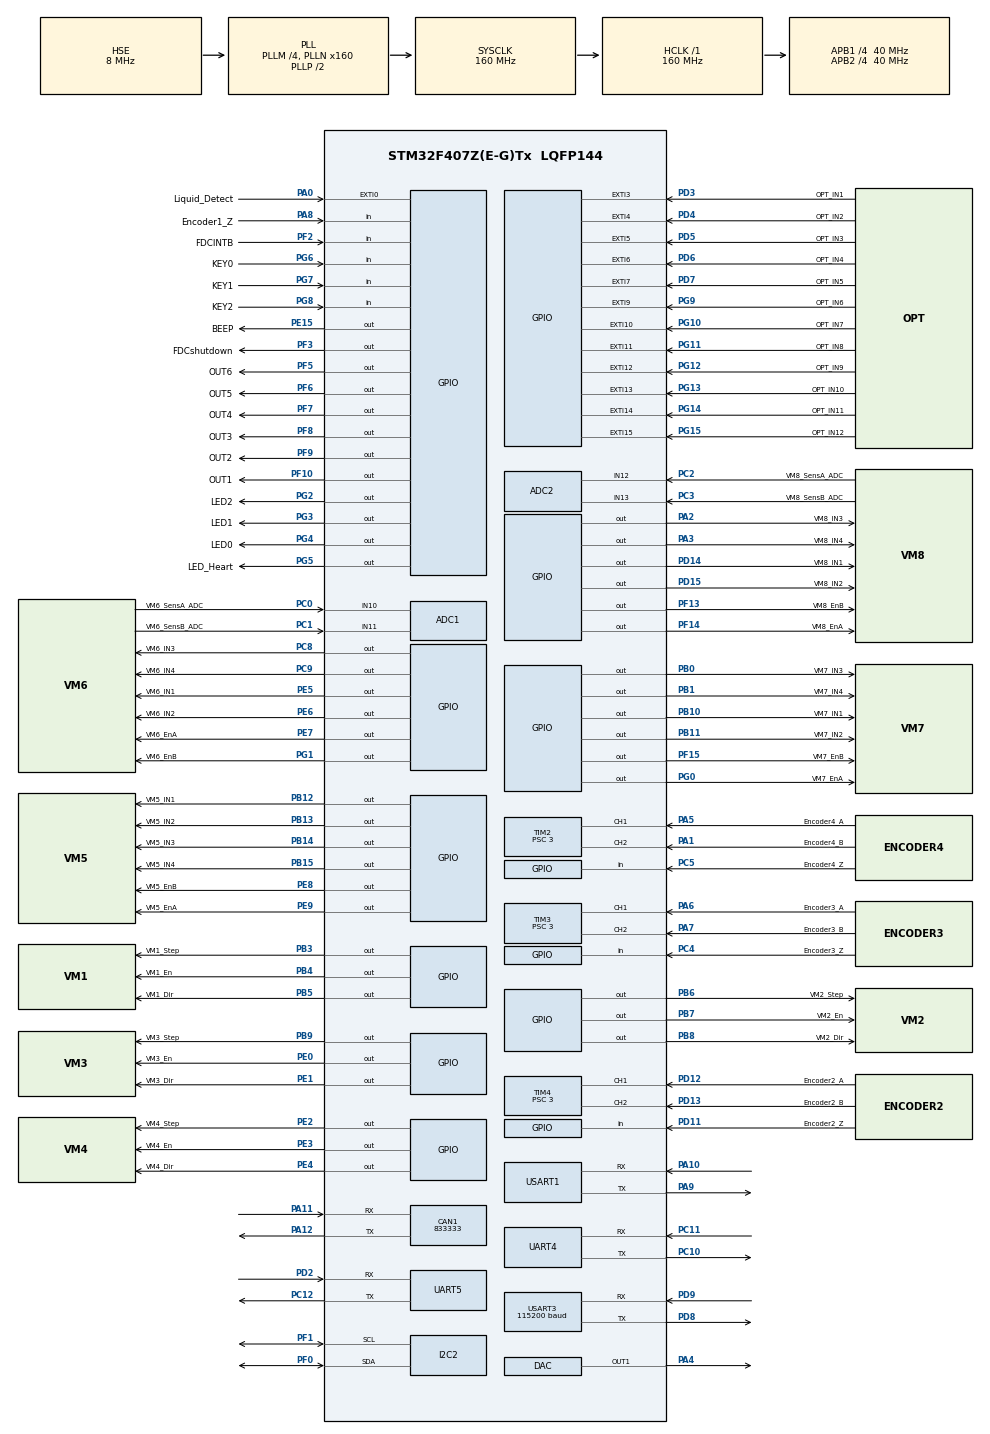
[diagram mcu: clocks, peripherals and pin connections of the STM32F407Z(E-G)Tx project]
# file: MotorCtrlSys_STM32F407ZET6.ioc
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ADC1.Channel-3\#ChannelRegularConversion=ADC_CHANNEL_10
ADC1.ClockPrescaler=ADC_CLOCK_SYNC_PCLK_DIV2
ADC1.ContinuousConvMode=DISABLE
ADC1.DMAContinuousRequests=DISABLE
ADC1.DiscontinuousConvMode=DISABLE
ADC1.EOCSelection=ADC_EOC_SINGLE_CONV
ADC1.NbrOfConversion=1
ADC1.NbrOfConversionFlag=1
ADC1.Rank-3\#ChannelRegularConversion=1
ADC1.SamplingTime-3\#ChannelRegularConversion=ADC_SAMPLETIME_15CYCLES
ADC1.ScanConvMode=DISABLE
ADC1.master=1
ADC2.Channel-2\#ChannelRegularConversion=ADC_CHANNEL_12
ADC2.NbrOfConversionFlag=1
ADC2.Rank-2\#ChannelRegularConversion=1
ADC2.SamplingTime-2\#ChannelRegularConversion=ADC_SAMPLETIME_3CYCLES
CAN1.BS1=CAN_BS1_1TQ
CAN1.BS2=CAN_BS2_1TQ
CAN1.CalculateBaudRate=833333
CAN1.CalculateTimeBit=1200
CAN1.CalculateTimeQuantum=400.0
Dma.I2C2_RX.0.Direction=DMA_PERIPH_TO_MEMORY
Dma.I2C2_RX.0.FIFOMode=DMA_FIFOMODE_DISABLE
Dma.I2C2_RX.0.Instance=DMA1_Stream2
Dma.I2C2_RX.0.MemDataAlignment=DMA_MDATAALIGN_BYTE
Dma.I2C2_RX.0.MemInc=DMA_MINC_ENABLE
Dma.I2C2_RX.0.Mode=DMA_CIRCULAR
Dma.I2C2_RX.0.PeriphDataAlignment=DMA_PDATAALIGN_BYTE
Dma.I2C2_RX.0.PeriphInc=DMA_PINC_DISABLE
Dma.I2C2_RX.0.Priority=DMA_PRIORITY_MEDIUM
Dma.Request0=I2C2_RX
FREERTOS.Tasks01=defaultTask,8,128,StartDefaultTask,Default,NULL,Dynamic,NULL,NULL;messageTask,24,512,StartmessageTask,As weak,NULL,Dynamic,NULL,NULL;myTask03,24,512,StartTask03,As weak,NULL,Dynamic,NULL,NULL;DetectionTask,8,512,StartDetectionTask,As weak,NULL,Dynamic,NULL,NULL
FREERTOS.configUSE_NEWLIB_REENTRANT=1
Mcu.Family=STM32F4
Mcu.Name=STM32F407Z(E-G)Tx
Mcu.Package=LQFP144
NVIC.DMA1_Stream2_IRQn=true\:7\:0\:true\:false\:true\:true\:false\:true\:true
NVIC.EXTI0_IRQn=true\:5\:0\:false\:false\:true\:true\:true\:true\:true
NVIC.EXTI15_10_IRQn=true\:5\:0\:false\:false\:true\:true\:true\:true\:true
NVIC.EXTI3_IRQn=true\:5\:0\:true\:false\:true\:true\:true\:true\:true
NVIC.EXTI4_IRQn=true\:5\:0\:false\:false\:true\:true\:true\:true\:true
NVIC.EXTI9_5_IRQn=true\:5\:0\:false\:false\:true\:true\:true\:true\:true
NVIC.I2C2_ER_IRQn=true\:5\:0\:true\:false\:true\:true\:true\:true\:true
NVIC.I2C2_EV_IRQn=true\:5\:0\:true\:false\:true\:true\:true\:true\:true
NVIC.PriorityGroup=NVIC_PRIORITYGROUP_4
NVIC.TIM1_BRK_TIM9_IRQn=true\:5\:0\:false\:false\:true\:true\:true\:true\:true
NVIC.TIM1_TRG_COM_TIM11_IRQn=true\:5\:0\:false\:false\:true\:true\:true\:true\:true
NVIC.TIM1_UP_TIM10_IRQn=true\:5\:0\:false\:false\:true\:false\:false\:true\:true
NVIC.TIM3_IRQn=true\:5\:0\:false\:false\:true\:true\:true\:true\:true
NVIC.TIM4_IRQn=true\:5\:0\:true\:false\:true\:true\:true\:true\:true
NVIC.TIM6_DAC_IRQn=true\:7\:0\:true\:false\:true\:true\:true\:true\:true
NVIC.TIM7_IRQn=true\:6\:0\:true\:false\:true\:true\:true\:true\:true
NVIC.TIM8_BRK_TIM12_IRQn=true\:5\:0\:false\:false\:true\:true\:true\:true\:true
NVIC.TIM8_TRG_COM_TIM14_IRQn=true\:5\:0\:false\:false\:true\:true\:true\:true\:true
NVIC.TIM8_UP_TIM13_IRQn=true\:5\:0\:false\:false\:true\:true\:true\:true\:true
NVIC.TimeBase=TIM1_UP_TIM10_IRQn
NVIC.TimeBaseIP=TIM1
NVIC.UART5_IRQn=true\:9\:0\:true\:false\:true\:true\:true\:true\:true
PA0-WKUP.GPIO_Label=Liquid_Detect
PA0-WKUP.GPIO_ModeDefaultEXTI=GPIO_MODE_IT_RISING_FALLING
PA0-WKUP.GPIO_PuPd=GPIO_PULLUP
PA0-WKUP.Signal=GPXTI0
PA1.GPIO_Label=Encoder4_B
PA1.Signal=S_TIM2_CH2
PA10.Mode=Asynchronous
PA10.Signal=USART1_RX
PA11.Mode=CAN_Activate
PA11.Signal=CAN1_RX
PA12.Mode=CAN_Activate
PA12.Signal=CAN1_TX
PA13.Mode=Serial_Wire
PA13.Signal=SYS_JTMS-SWDIO
PA14.Mode=Serial_Wire
PA14.Signal=SYS_JTCK-SWCLK
PA2.GPIO_Label=VM8_IN3
PA2.GPIO_Speed=GPIO_SPEED_FREQ_HIGH
PA2.Signal=GPIO_Output
PA3.GPIO_Label=VM8_IN4
PA3.GPIO_Speed=GPIO_SPEED_FREQ_HIGH
PA3.Signal=GPIO_Output
PA4.Signal=COMP_DAC1_group
PA5.GPIO_Label=Encoder4_A
PA5.Signal=S_TIM2_CH1_ETR
PA6.GPIO_Label=Encoder3_A
PA6.Signal=S_TIM3_CH1
PA7.GPIO_Label=Encoder3_B
PA7.Signal=S_TIM3_CH2
PA8.GPIO_Label=Encoder1_Z
PA8.Signal=GPIO_Input
PA9.Mode=Asynchronous
PA9.Signal=USART1_TX
PB0.GPIO_Label=VM7_IN3
PB0.GPIO_Speed=GPIO_SPEED_FREQ_HIGH
PB0.Signal=GPIO_Output
PB1.GPIO_Label=VM7_IN4
PB1.GPIO_Speed=GPIO_SPEED_FREQ_HIGH
PB1.Signal=GPIO_Output
PB10.GPIO_Label=VM7_IN1
PB10.GPIO_Speed=GPIO_SPEED_FREQ_HIGH
PB10.Signal=GPIO_Output
PB11.GPIO_Label=VM7_IN2
PB11.GPIO_Speed=GPIO_SPEED_FREQ_HIGH
PB11.Signal=GPIO_Output
PB12.GPIO_Label=VM5_IN1
PB12.GPIO_Speed=GPIO_SPEED_FREQ_HIGH
PB12.Signal=GPIO_Output
PB13.GPIO_Label=VM5_IN2
PB13.GPIO_Speed=GPIO_SPEED_FREQ_HIGH
PB13.Signal=GPIO_Output
PB14.GPIO_Label=VM5_IN3
PB14.GPIO_Speed=GPIO_SPEED_FREQ_HIGH
PB14.Signal=GPIO_Output
PB15.GPIO_Label=VM5_IN4
PB15.GPIO_Speed=GPIO_SPEED_FREQ_HIGH
PB15.Signal=GPIO_Output
PB3.GPIO_Label=VM1_Step
PB3.GPIO_Speed=GPIO_SPEED_FREQ_VERY_HIGH
PB3.Signal=GPIO_Output
PB4.GPIO_Label=VM1_En
PB4.PinState=GPIO_PIN_SET
PB4.Signal=GPIO_Output
PB5.GPIO_Label=VM1_Dir
PB5.Signal=GPIO_Output
PB6.GPIO_Label=VM2_Step
PB6.GPIO_Speed=GPIO_SPEED_FREQ_VERY_HIGH
PB6.Signal=GPIO_Output
PB7.GPIO_Label=VM2_En
PB7.PinState=GPIO_PIN_SET
PB7.Signal=GPIO_Output
PB8.GPIO_Label=VM2_Dir
PB8.Signal=GPIO_Output
PB9.GPIO_Label=VM3_Step
PB9.GPIO_Speed=GPIO_SPEED_FREQ_VERY_HIGH
PB9.Signal=GPIO_Output
PC0.GPIO_Label=VM6_SensA_ADC
PC0.Signal=ADCx_IN10
PC1.GPIO_Label=VM6_SensB_ADC
PC1.Signal=ADCx_IN11
PC10.Mode=Asynchronous
PC10.Signal=UART4_TX
PC11.Mode=Asynchronous
PC11.Signal=UART4_RX
PC12.Mode=Asynchronous
PC12.Signal=UART5_TX
PC14-OSC32_IN.Mode=LSE-External-Oscillator
PC14-OSC32_IN.Signal=RCC_OSC32_IN
PC15-OSC32_OUT.Mode=LSE-External-Oscillator
PC15-OSC32_OUT.Signal=RCC_OSC32_OUT
PC2.GPIO_Label=VM8_SensA_ADC
PC2.Signal=ADCx_IN12
PC3.GPIO_Label=VM8_SensB_ADC
PC3.Signal=ADCx_IN13
PC4.GPIO_Label=Encoder3_Z
PC4.Signal=GPIO_Input
PC5.GPIO_Label=Encoder4_Z
PC5.Signal=GPIO_Input
PC8.GPIO_Label=VM6_IN3
PC8.GPIO_Speed=GPIO_SPEED_FREQ_HIGH
PC8.Signal=GPIO_Output
PC9.GPIO_Label=VM6_IN4
PC9.GPIO_Speed=GPIO_SPEED_FREQ_HIGH
PC9.Signal=GPIO_Output
PD11.GPIO_Label=Encoder2_Z
PD11.Signal=GPIO_Input
PD12.GPIO_Label=Encoder2_A
PD12.Signal=S_TIM4_CH1
PD13.GPIO_Label=Encoder2_B
PD13.Signal=S_TIM4_CH2
PD14.GPIO_Label=VM8_IN1
PD14.GPIO_Speed=GPIO_SPEED_FREQ_HIGH
PD14.Signal=GPIO_Output
PD15.GPIO_Label=VM8_IN2
PD15.GPIO_Speed=GPIO_SPEED_FREQ_HIGH
PD15.Signal=GPIO_Output
PD2.Mode=Asynchronous
PD2.Signal=UART5_RX
PD3.GPIO_Label=OPT_IN1
PD3.GPIO_ModeDefaultEXTI=GPIO_MODE_IT_RISING_FALLING
PD3.Signal=GPXTI3
PD4.GPIO_Label=OPT_IN2
PD4.GPIO_ModeDefaultEXTI=GPIO_MODE_IT_RISING_FALLING
PD4.Signal=GPXTI4
PD5.GPIO_Label=OPT_IN3
PD5.GPIO_ModeDefaultEXTI=GPIO_MODE_IT_RISING_FALLING
PD5.Signal=GPXTI5
PD6.GPIO_Label=OPT_IN4
PD6.GPIO_ModeDefaultEXTI=GPIO_MODE_IT_RISING_FALLING
PD6.Signal=GPXTI6
PD7.GPIO_Label=OPT_IN5
PD7.GPIO_ModeDefaultEXTI=GPIO_MODE_IT_RISING_FALLING
PD7.Signal=GPXTI7
PD8.Mode=Asynchronous
PD8.Signal=USART3_TX
PD9.Mode=Asynchronous
PD9.Signal=USART3_RX
PE0.GPIO_Label=VM3_En
PE0.PinState=GPIO_PIN_SET
PE0.Signal=GPIO_Output
PE1.GPIO_Label=VM3_Dir
PE1.Signal=GPIO_Output
PE15.GPIO_Label=BEEP
PE15.Signal=GPIO_Output
PE2.GPIO_Label=VM4_Step
PE2.GPIO_Speed=GPIO_SPEED_FREQ_VERY_HIGH
PE2.Signal=GPIO_Output
PE3.GPIO_Label=VM4_En
PE3.PinState=GPIO_PIN_SET
PE3.Signal=GPIO_Output
PE4.GPIO_Label=VM4_Dir
PE4.Signal=GPIO_Output
PE5.GPIO_Label=VM6_IN1
PE5.GPIO_Speed=GPIO_SPEED_FREQ_HIGH
PE5.Signal=GPIO_Output
PE6.GPIO_Label=VM6_IN2
PE6.GPIO_Speed=GPIO_SPEED_FREQ_HIGH
PE6.Signal=GPIO_Output
PE7.GPIO_Label=VM6_EnA
PE7.GPIO_ModeDefaultOutputPP=GPIO_MODE_OUTPUT_PP
PE7.GPIO_PuPd=GPIO_PULLDOWN
PE7.GPIO_Speed=GPIO_SPEED_FREQ_LOW
PE7.PinState=GPIO_PIN_RESET
PE7.Signal=GPIO_Output
PE8.GPIO_Label=VM5_EnB
PE8.GPIO_ModeDefaultOutputPP=GPIO_MODE_OUTPUT_PP
PE8.GPIO_PuPd=GPIO_PULLDOWN
PE8.GPIO_Speed=GPIO_SPEED_FREQ_LOW
PE8.PinState=GPIO_PIN_RESET
PE8.Signal=GPIO_Output
PE9.GPIO_Label=VM5_EnA
PE9.GPIO_ModeDefaultOutputPP=GPIO_MODE_OUTPUT_PP
PE9.GPIO_PuPd=GPIO_PULLDOWN
PE9.GPIO_Speed=GPIO_SPEED_FREQ_LOW
PE9.PinState=GPIO_PIN_RESET
PE9.Signal=GPIO_Output
PF0.Mode=I2C
PF0.Signal=I2C2_SDA
PF1.Mode=I2C
PF1.Signal=I2C2_SCL
PF10.GPIO_Label=OUT1
PF10.GPIO_ModeDefaultOutputPP=GPIO_MODE_OUTPUT_PP
PF10.GPIO_PuPd=GPIO_PULLDOWN
PF10.GPIO_Speed=GPIO_SPEED_FREQ_LOW
PF10.PinState=GPIO_PIN_RESET
PF10.Signal=GPIO_Output
PF13.GPIO_Label=VM8_EnB
PF13.GPIO_ModeDefaultOutputPP=GPIO_MODE_OUTPUT_PP
PF13.GPIO_PuPd=GPIO_PULLDOWN
PF13.GPIO_Speed=GPIO_SPEED_FREQ_LOW
PF13.PinState=GPIO_PIN_RESET
PF13.Signal=GPIO_Output
PF14.GPIO_Label=VM8_EnA
PF14.GPIO_ModeDefaultOutputPP=GPIO_MODE_OUTPUT_PP
PF14.GPIO_PuPd=GPIO_PULLDOWN
PF14.GPIO_Speed=GPIO_SPEED_FREQ_LOW
PF14.PinState=GPIO_PIN_RESET
PF14.Signal=GPIO_Output
PF15.GPIO_Label=VM7_EnB
PF15.GPIO_ModeDefaultOutputPP=GPIO_MODE_OUTPUT_PP
PF15.GPIO_PuPd=GPIO_PULLDOWN
PF15.GPIO_Speed=GPIO_SPEED_FREQ_LOW
PF15.PinState=GPIO_PIN_RESET
PF15.Signal=GPIO_Output
PF2.GPIO_Label=FDCINTB
PF2.Signal=GPIO_Input
PF3.GPIO_Label=FDCshutdown
PF3.Signal=GPIO_Output
PF5.GPIO_Label=OUT6
PF5.GPIO_ModeDefaultOutputPP=GPIO_MODE_OUTPUT_PP
PF5.GPIO_PuPd=GPIO_PULLDOWN
PF5.GPIO_Speed=GPIO_SPEED_FREQ_LOW
PF5.PinState=GPIO_PIN_RESET
PF5.Signal=GPIO_Output
PF6.GPIO_Label=OUT5
PF6.GPIO_ModeDefaultOutputPP=GPIO_MODE_OUTPUT_PP
PF6.GPIO_PuPd=GPIO_PULLDOWN
PF6.GPIO_Speed=GPIO_SPEED_FREQ_LOW
PF6.PinState=GPIO_PIN_RESET
PF6.Signal=GPIO_Output
PF7.GPIO_Label=OUT4
PF7.GPIO_ModeDefaultOutputPP=GPIO_MODE_OUTPUT_PP
PF7.GPIO_PuPd=GPIO_PULLDOWN
PF7.GPIO_Speed=GPIO_SPEED_FREQ_LOW
PF7.PinState=GPIO_PIN_RESET
PF7.Signal=GPIO_Output
PF8.GPIO_Label=OUT3
PF8.GPIO_ModeDefaultOutputPP=GPIO_MODE_OUTPUT_PP
PF8.GPIO_PuPd=GPIO_PULLDOWN
PF8.GPIO_Speed=GPIO_SPEED_FREQ_LOW
PF8.PinState=GPIO_PIN_RESET
PF8.Signal=GPIO_Output
PF9.GPIO_Label=OUT2
PF9.GPIO_ModeDefaultOutputPP=GPIO_MODE_OUTPUT_PP
PF9.GPIO_PuPd=GPIO_PULLDOWN
PF9.GPIO_Speed=GPIO_SPEED_FREQ_LOW
PF9.PinState=GPIO_PIN_RESET
PF9.Signal=GPIO_Output
PG0.GPIO_Label=VM7_EnA
PG0.GPIO_ModeDefaultOutputPP=GPIO_MODE_OUTPUT_PP
PG0.GPIO_PuPd=GPIO_PULLDOWN
PG0.GPIO_Speed=GPIO_SPEED_FREQ_LOW
PG0.PinState=GPIO_PIN_RESET
PG0.Signal=GPIO_Output
PG1.GPIO_Label=VM6_EnB
PG1.GPIO_ModeDefaultOutputPP=GPIO_MODE_OUTPUT_PP
PG1.GPIO_PuPd=GPIO_PULLDOWN
PG1.GPIO_Speed=GPIO_SPEED_FREQ_LOW
PG1.PinState=GPIO_PIN_RESET
PG1.Signal=GPIO_Output
PG10.GPIO_Label=OPT_IN7
PG10.GPIO_ModeDefaultEXTI=GPIO_MODE_IT_RISING_FALLING
PG10.Signal=GPXTI10
PG11.GPIO_Label=OPT_IN8
PG11.GPIO_ModeDefaultEXTI=GPIO_MODE_IT_RISING_FALLING
PG11.Signal=GPXTI11
PG12.GPIO_Label=OPT_IN9
PG12.GPIO_ModeDefaultEXTI=GPIO_MODE_IT_RISING_FALLING
PG12.Signal=GPXTI12
PG13.GPIO_Label=OPT_IN10
PG13.GPIO_ModeDefaultEXTI=GPIO_MODE_IT_RISING_FALLING
PG13.Signal=GPXTI13
PG14.GPIO_Label=OPT_IN11
PG14.GPIO_ModeDefaultEXTI=GPIO_MODE_IT_RISING_FALLING
PG14.Signal=GPXTI14
PG15.GPIO_Label=OPT_IN12
PG15.GPIO_ModeDefaultEXTI=GPIO_MODE_IT_RISING_FALLING
PG15.Signal=GPXTI15
PG2.GPIO_Label=LED2
PG2.PinState=GPIO_PIN_SET
PG2.Signal=GPIO_Output
PG3.GPIO_Label=LED1
PG3.PinState=GPIO_PIN_SET
PG3.Signal=GPIO_Output
PG4.GPIO_Label=LED0
PG4.PinState=GPIO_PIN_SET
PG4.Signal=GPIO_Output
PG5.GPIO_Label=LED_Heart
PG5.Signal=GPIO_Output
PG6.GPIO_Label=KEY0
PG6.GPIO_PuPd=GPIO_PULLUP
PG6.Signal=GPIO_Input
PG7.GPIO_Label=KEY1
PG7.GPIO_PuPd=GPIO_PULLUP
PG7.Signal=GPIO_Input
PG8.GPIO_Label=KEY2
PG8.GPIO_PuPd=GPIO_PULLUP
PG8.Signal=GPIO_Input
PG9.GPIO_Label=OPT_IN6
PG9.GPIO_ModeDefaultEXTI=GPIO_MODE_IT_RISING_FALLING
PG9.Signal=GPXTI9
PH0-OSC_IN.Mode=HSE-External-Oscillator
PH0-OSC_IN.Signal=RCC_OSC_IN
PH1-OSC_OUT.Mode=HSE-External-Oscillator
PH1-OSC_OUT.Signal=RCC_OSC_OUT
ProjectManager.HeapSize=0x200
ProjectManager.StackSize=0x400
ProjectManager.TargetToolchain=STM32CubeIDE
RCC.48MHZClocksFreq_Value=80000000
RCC.AHBFreq_Value=160000000
RCC.APB1CLKDivider=RCC_HCLK_DIV4
RCC.APB1Freq_Value=40000000
RCC.APB1TimFreq_Value=80000000
RCC.APB2CLKDivider=RCC_HCLK_DIV4
RCC.APB2Freq_Value=40000000
RCC.APB2TimFreq_Value=80000000
RCC.CortexFreq_Value=160000000
RCC.HCLKFreq_Value=160000000
RCC.HSE_VALUE=8000000
RCC.HSI_VALUE=16000000
RCC.PLLM=4
RCC.PLLN=160
RCC.PLLSourceVirtual=RCC_PLLSOURCE_HSE
RCC.SYSCLKFreq_VALUE=160000000
RCC.SYSCLKSource=RCC_SYSCLKSOURCE_PLLCLK
RCC.VCOOutputFreq_Value=320000000
SH.ADCx_IN10.0=ADC1_IN10,IN10
SH.ADCx_IN11.0=ADC1_IN11,IN11
SH.ADCx_IN12.0=ADC2_IN12,IN12
SH.ADCx_IN13.0=ADC2_IN13,IN13
SH.COMP_DAC1_group.0=DAC_OUT1,DAC_OUT1
SH.S_TIM2_CH1_ETR.0=TIM2_CH1,Encoder_Interface
SH.S_TIM2_CH2.0=TIM2_CH2,Encoder_Interface
SH.S_TIM3_CH1.0=TIM3_CH1,Encoder_Interface
SH.S_TIM3_CH2.0=TIM3_CH2,Encoder_Interface
SH.S_TIM4_CH1.0=TIM4_CH1,Encoder_Interface
SH.S_TIM4_CH2.0=TIM4_CH2,Encoder_Interface
TIM10.Period=9
TIM10.Prescaler=79
TIM11.Period=9
TIM11.Prescaler=79
TIM12.Period=9
TIM12.Prescaler=79
TIM13.Period=9
TIM13.Prescaler=79
TIM14.Period=9
TIM14.Prescaler=79
TIM2.Period=65535
TIM2.Prescaler=3
TIM3.CounterMode=TIM_COUNTERMODE_UP
TIM3.EncoderMode=TIM_ENCODERMODE_TI12
TIM3.IC1Filter=15
TIM3.IC2Filter=15
TIM3.Prescaler=3
TIM4.EncoderMode=TIM_ENCODERMODE_TI12
TIM4.IC1Filter=15
TIM4.IC2Filter=15
TIM4.Period=65535
TIM4.Prescaler=3
TIM6.Period=9
TIM6.Prescaler=79
TIM7.Period=9
TIM7.Prescaler=79
TIM9.Period=99
TIM9.Prescaler=79
UART4.VirtualMode=Asynchronous
UART5.VirtualMode=Asynchronous
USART1.VirtualMode=VM_ASYNC
USART3.BaudRate=115200
USART3.VirtualMode=VM_ASYNC
VP_FREERTOS_VS_CMSIS_V2.Mode=CMSIS_V2
VP_SYS_VS_tim1.Mode=TIM1
VP_TIM10_VS_ClockSourceINT.Mode=Enable_Timer
VP_TIM11_VS_ClockSourceINT.Mode=Enable_Timer
VP_TIM12_VS_ClockSourceINT.Mode=Internal
VP_TIM13_VS_ClockSourceINT.Mode=Enable_Timer
VP_TIM14_VS_ClockSourceINT.Mode=Enable_Timer
VP_TIM6_VS_ClockSourceINT.Mode=Enable_Timer
VP_TIM7_VS_ClockSourceINT.Mode=Enable_Timer
VP_TIM9_VS_ClockSourceINT.Mode=Internal
board=custom

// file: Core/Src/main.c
/* USER CODE BEGIN Header */
/**
  ******************************************************************************
  * @file           : main.c
  * @brief          : Main program body
  ******************************************************************************
  * @attention
  *
  * Copyright (c) 2022 STMicroelectronics.
  * All rights reserved.
  *
  * This software is licensed under terms that can be found in the LICENSE file
  * in the root directory of this software component.
  * If no LICENSE file comes with this software, it is provided AS-IS.
  *
  ******************************************************************************
  */
/* USER CODE END Header */
#include "main.h"
#include "cmsis_os.h"
#include "adc.h"
#include "can.h"
#include "dac.h"
#include "dma.h"
#include "i2c.h"
#include "tim.h"
#include "usart.h"
#include "gpio.h"

/* USER CODE BEGIN PTD */
#ifdef __GNUC__
#define PUTCHAR_PROTOTYPE int __io_putchar(int ch)
#else
#define PUTCHAR_PROTOTYPE int fputc(int ch, FILE *f)
#endif

PUTCHAR_PROTOTYPE
{
	HAL_UART_Transmit(&huart5, (uint8_t*)&ch,1,HAL_MAX_DELAY);
    return ch;
}
/* USER CODE END PTD */

void SystemClock_Config(void);
void MX_FREERTOS_Init(void);

int main(void)
{

  /* MCU Configuration--------------------------------------------------------*/

  /* Reset of all peripherals, Initializes the Flash interface and the Systick. */
  HAL_Init();

  /* USER CODE BEGIN Init */
  //HAL_Delay(6000);
  /* USER CODE END Init */

  /* Configure the system clock */
  SystemClock_Config();

  /* USER CODE BEGIN SysInit */
  MX_GPIO_Init();
  MX_DMA_Init();
  MX_CAN1_Init();
  MX_USART1_UART_Init();
  MX_DAC_Init();
  MX_TIM2_Init();
  MX_TIM3_Init();
  MX_TIM4_Init();
  MX_UART4_Init();
  MX_UART5_Init();
  MX_USART3_UART_Init();
  MX_ADC1_Init();
  MX_ADC2_Init();
  MX_I2C2_Init();
  MX_TIM10_Init();
  MX_TIM11_Init();
  MX_TIM13_Init();
  MX_TIM14_Init();
  MX_TIM9_Init();
  MX_TIM7_Init();
  MX_TIM6_Init();
  MX_TIM12_Init();
#ifdef XXX
  /* USER CODE END SysInit */

  /* Initialize all configured peripherals */
  MX_GPIO_Init();
  MX_DMA_Init();
  MX_USART1_UART_Init();
  MX_DAC_Init();
  MX_TIM2_Init();
  MX_TIM3_Init();
  MX_TIM4_Init();
  MX_UART4_Init();
  MX_UART5_Init();
  MX_USART3_UART_Init();
  MX_ADC1_Init();
  MX_ADC2_Init();
  MX_I2C2_Init();
  MX_TIM10_Init();
  MX_TIM11_Init();
  MX_TIM13_Init();
  MX_TIM14_Init();
  MX_TIM9_Init();
  MX_CAN1_Init();
  MX_TIM7_Init();
  MX_TIM6_Init();
  MX_TIM12_Init();
  /* USER CODE BEGIN 2 */
#endif
  ALL_Motors_Disable();

  /* USER CODE END 2 */

  /* Init scheduler */
  osKernelInitialize();  /* Call init function for freertos objects (in freertos.c) */
  MX_FREERTOS_Init();

  /* Start scheduler */
  osKernelStart();

  /* We should never get here as control is now taken by the scheduler */
  /* Infinite loop */
  while (1)
  {

  }
}

void SystemClock_Config(void)
{
  RCC_OscInitTypeDef RCC_OscInitStruct = {0};
  RCC_ClkInitTypeDef RCC_ClkInitStruct = {0};

  /** Configure the main internal regulator output voltage
  */
  __HAL_RCC_PWR_CLK_ENABLE();
  __HAL_PWR_VOLTAGESCALING_CONFIG(PWR_REGULATOR_VOLTAGE_SCALE1);

  /** Initializes the RCC Oscillators according to the specified parameters
  * in the RCC_OscInitTypeDef structure.
  */
  RCC_OscInitStruct.OscillatorType = RCC_OSCILLATORTYPE_HSE;
  RCC_OscInitStruct.HSEState = RCC_HSE_ON;
  RCC_OscInitStruct.PLL.PLLState = RCC_PLL_ON;
  RCC_OscInitStruct.PLL.PLLSource = RCC_PLLSOURCE_HSE;
  RCC_OscInitStruct.PLL.PLLM = 4;
  RCC_OscInitStruct.PLL.PLLN = 160;
  RCC_OscInitStruct.PLL.PLLP = RCC_PLLP_DIV2;
  RCC_OscInitStruct.PLL.PLLQ = 4;
  if (HAL_RCC_OscConfig(&RCC_OscInitStruct) != HAL_OK)
  {
    Error_Handler();
  }

  /** Initializes the CPU, AHB and APB buses clocks
  */
  RCC_ClkInitStruct.ClockType = RCC_CLOCKTYPE_HCLK|RCC_CLOCKTYPE_SYSCLK
                              |RCC_CLOCKTYPE_PCLK1|RCC_CLOCKTYPE_PCLK2;
  RCC_ClkInitStruct.SYSCLKSource = RCC_SYSCLKSOURCE_PLLCLK;
  RCC_ClkInitStruct.AHBCLKDivider = RCC_SYSCLK_DIV1;
  RCC_ClkInitStruct.APB1CLKDivider = RCC_HCLK_DIV4;
  RCC_ClkInitStruct.APB2CLKDivider = RCC_HCLK_DIV4;

  if (HAL_RCC_ClockConfig(&RCC_ClkInitStruct, FLASH_LATENCY_5) != HAL_OK)
  {
    Error_Handler();
  }
}

/* USER CODE BEGIN 4 */

uint32_t uart_reieve_timeoutCount = 0;
uint32_t Pluse_High = 2; // 高电平时10-20us
uint32_t timecount_TIM10 = 0;
uint32_t AccelDecelcount_TIM10 = 0;
uint32_t timecount_TIM11 = 0;
uint32_t AccelDecelcount_TIM11 = 0;
uint32_t timecount_TIM12 = 0;
uint32_t AccelDecelcount_TIM12 = 0;
uint8_t  Motor7_State = 1 ;
uint32_t timecount_TIM13 = 0;
uint32_t AccelDecelcount_TIM13 = 0;
uint32_t timecount_TIM14 = 0;
uint32_t AccelDecelcount_TIM14 = 0;
uint32_t timecount_TIM6 = 0;
uint32_t AccelDecelcount_TIM6 = 0;
uint8_t  Motor5_State = 1 ;
uint32_t timecount_TIM7 = 0;
uint32_t AccelDecelcount_TIM7 = 0;

#ifdef L298N_StepMotorCtrl
int  Motor6_State = 0 ;
#else
int  Motor6_State = 1 ;
#endif

//直流电机控制
uint32_t timecount_TIM12_DCM6 = 0 ;
uint32_t timecount_TIM12_DCM7 = 0 ;
uint32_t timecount_TIM12_DCM8 = 0 ;

/* USER CODE END 4 */

void HAL_TIM_PeriodElapsedCallback(TIM_HandleTypeDef *htim)
{
  if (htim->Instance == TIM1) {
    HAL_IncTick();
  }
  /* USER CODE BEGIN Callback 1 */

	if (htim->Instance == TIM9) {	// 计时器周期为0.1ms
		uart_reieve_timeoutCount++;
		if( (USART_RX_STA&0x8000) || (USART_RX_STA==0) ){	// 判断串口接收超时
			uart_reieve_timeoutCount = 0;
			HAL_TIM_Base_Stop_IT(&htim9);
		}
		else{
			if(uart_reieve_timeoutCount > 5000){
				printf("[WRONG] Data Input Timeout ! \r\n");
				uart_reieve_timeoutCount = 0;
				USART_RX_STA = 0;
				HAL_TIM_Base_Stop_IT(&htim9);
			}
		}
	}

	if (htim->Instance == TIM10)
	{
			timecount_TIM10++;
			AccelDecelcount_TIM10++;
			if(timecount_TIM10 <= Pluse_High)
			{
				Motorpluse1_High();
			}
			else if(timecount_TIM10 > Pluse_High)
			{
				Motorpluse1_Low();
			}
			if(timecount_TIM10 >= Motor[1].StepperSpeedTMR)
			{
				timecount_TIM10 = 0 ;
				Motor[1].NumberofSteps--;
				if (Motor[1].MotorDirection == 1){
					Motor[1].StepPosition++;
					if (Motor[1].StepPosition >= Motor[1].StepsInOneCircle){
						Motor[1].StepPosition = Motor[1].StepPosition - Motor[1].StepsInOneCircle ;
					}
				}
				else{
					Motor[1].StepPosition--;
					if (Motor[1].StepPosition < 0){
						Motor[1].StepPosition = Motor[1].StepPosition + Motor[1].StepsInOneCircle ;
					}
				}
			}
			if(Motor[1].StepPosition == Motor[1].TargetPosition)
			{
				Motor[1].Status = 0;
				printf("---Motor1 Steps Position:%ld---\r\n",Motor[1].StepPosition);
				HAL_TIM_Base_Stop_IT(&htim10);
			}
			else if (Motor[1].NumberofSteps <= 0){
				Motor[1].Status = 0;
				//printf("[WRONG]Motor1 Goto Target Position Failed!---Current_Position:%ld---\r\n",Motor[1].StepPosition);
				HAL_TIM_Base_Stop_IT(&htim10);
			}

			if (Motor[1].NumberofSteps > Motor[1].NumberofSteps_StopAccel)  // if.. begin Acceleration
			{
				if(AccelDecelcount_TIM10 >= Motor[1].AccelerationTimeTMR)
				{
					AccelDecelcount_TIM10=0;
					AccelDecel(ACCEL,&Motor[1]);
				}
			}
			else if (Motor[1].NumberofSteps < Motor[1].NumberofSteps_BeginDecel)  // if.. begin Deceleration
			{
				if(AccelDecelcount_TIM10 >= Motor[1].DecelerationTimeTMR)
				{
					AccelDecelcount_TIM10=0;
					AccelDecel(DECEL,&Motor[1]);
				}
			}

	}

	else if (htim->Instance == TIM11)
	{
			timecount_TIM11++;
			AccelDecelcount_TIM11++;
			if(timecount_TIM11 <= Pluse_High)
			{
				Motorpluse2_High();
			}
			else if(timecount_TIM11 > Pluse_High)
			{
				Motorpluse2_Low();
			}
			if(timecount_TIM11 >= Motor[2].StepperSpeedTMR)
			{
				timecount_TIM11 = 0 ;
				Motor[2].NumberofSteps--;
#ifndef JiaYangZhen_EncoderMode
				if (Motor[2].MotorDirection == 1){
					Motor[2].StepPosition++;
				}
				else{
					Motor[2].StepPosition--;
				}
#endif
			}

			if(Motor[2].StepPosition == Motor[2].TargetPosition){
				Motor[2].Status = 0;
				printf("---Motor2 Steps Position:%ld---\r\n",Motor[2].StepPosition);
				HAL_TIM_Base_Stop_IT(&htim11);
			}
			else if (Motor[2].NumberofSteps <= 0){
				Motor[2].Status = 0;
				//printf("[WRONG]Motor2 Goto Target Position Failed!---Current_Position:%ld---\r\n",Motor[2].StepPosition);
				HAL_TIM_Base_Stop_IT(&htim11);
			}

			if (Motor[2].NumberofSteps > Motor[2].NumberofSteps_StopAccel)
			{
				if(AccelDecelcount_TIM11 >= Motor[2].AccelerationTimeTMR)
				{
					AccelDecelcount_TIM11=0;
					AccelDecel(ACCEL,&Motor[2]);
				}
			}
			else if (Motor[2].NumberofSteps < Motor[2].NumberofSteps_BeginDecel)
			{
				if(AccelDecelcount_TIM11 >= Motor[2].DecelerationTimeTMR)
				{
					AccelDecelcount_TIM11=0;
					AccelDecel(DECEL,&Motor[2]);
				}
			}

	}

	else if (htim->Instance == TIM13)
	{
			timecount_TIM13++;
			AccelDecelcount_TIM13++;
#ifdef JiaYangZhen
//			if (Motor[3].StepPosition > 7000){
//				printf("[WRONG]OverTrip!!!,Motor[3].StepPosition:%ld\r\n",Motor[3].StepPosition);
//				Motor[3].Status = 0;
//				HAL_TIM_Base_Stop_IT(&htim13);
//			}

			if (DetectionTask_STATE == Cap0_Sample_State){
				switch (Follow_state){
				case 1:
					if(timecount_TIM13 <= Pluse_High){
						Motorpluse3_High();
					}
					else if(timecount_TIM13 > Pluse_High){
						Motorpluse3_Low();
					}
					if(timecount_TIM13 >= Motor[3].StepperSpeedTMR){
						timecount_TIM13 = 0 ;
#ifndef JiaYangZhen_EncoderMode
						Motor[3].StepPosition++;
#endif
					}
					break;
				case 2:
					timecount_TIM13 = 0 ;
					//使用IO输出模块进行液面�???????????�???????????
//					HAL_TIM_Base_Stop_IT(&htim13);
//					Motor[3].Status = 0;
					break;
				case 3:
					if(timecount_TIM13 <= Pluse_High){
						Motorpluse3_High();
					}
					else if(timecount_TIM13 > Pluse_High){
						Motorpluse3_Low();
					}
					if(timecount_TIM13 >= Motor[3].StepperSpeedTMR){
						timecount_TIM13 = 0 ;
#ifndef JiaYangZhen_EncoderMode
							Motor[3].StepPosition--;
#endif
					}
					break;
				}
			}
			else
#endif
			{
				if(timecount_TIM13 <= Pluse_High){
					Motorpluse3_High();
				}
				else if(timecount_TIM13 > Pluse_High){
					Motorpluse3_Low();
				}
				if(timecount_TIM13 >= Motor[3].StepperSpeedTMR){
					timecount_TIM13 = 0 ;
					Motor[3].NumberofSteps--;
#ifndef JiaYangZhen_EncoderMode
					if (Motor[3].MotorDirection == 1){
						Motor[3].StepPosition++;
					}
					else{
						Motor[3].StepPosition--;
					}
#endif
				}

				if(Motor[3].StepPosition == Motor[3].TargetPosition){
					Motor[3].Status = 0;
					printf("---Motor3 Steps Position:%ld---\r\n",Motor[3].StepPosition);
					HAL_TIM_Base_Stop_IT(&htim13);
				}
				else if (Motor[3].NumberofSteps <= 0){
					Motor[3].Status = 0;
					printf("[WRONG]Motor3 Goto Target Position Failed!---Current_Position:%ld---\r\n",Motor[3].StepPosition);
					HAL_TIM_Base_Stop_IT(&htim13);
				}

				if (Motor[3].NumberofSteps > Motor[3].NumberofSteps_StopAccel){
					if(AccelDecelcount_TIM13 >= Motor[3].AccelerationTimeTMR){
						AccelDecelcount_TIM13=0;
						AccelDecel(ACCEL,&Motor[3]);
					}
				}
				else if (Motor[3].NumberofSteps < Motor[3].NumberofSteps_BeginDecel){
					if(AccelDecelcount_TIM13 >= Motor[3].DecelerationTimeTMR){
						AccelDecelcount_TIM13=0;
						AccelDecel(DECEL,&Motor[3]);
					}
				}
			}

	}

	else if (htim->Instance == TIM14)
	{
			timecount_TIM14++;
			AccelDecelcount_TIM14++;
			if(timecount_TIM14 <= Pluse_High)
			{
				Motorpluse4_High();
			}
			else if(timecount_TIM14 > Pluse_High)
			{
				Motorpluse4_Low();
			}
			if(timecount_TIM14 >= Motor[4].StepperSpeedTMR)
			{
				timecount_TIM14 = 0 ;
				Motor[4].NumberofSteps--;
				if (Motor[4].MotorDirection == 1){
					Motor[4].StepPosition++;
				}
				else{
					Motor[4].StepPosition--;
				}
			}
			if(Motor[4].StepPosition == Motor[4].TargetPosition)
			{
				Motor[4].Status = 0;
				//printf("---Motor4 Steps Position:%ld---\r\n",Motor[4].StepPosition);
				HAL_TIM_Base_Stop_IT(&htim14);
			}
			else if (Motor[4].NumberofSteps <= 0){
				Motor[4].Status = 0;
				printf("[WRONG]Motor4 Goto Target Position Failed!---Current_Position:%ld---\r\n",Motor[4].StepPosition);
				HAL_TIM_Base_Stop_IT(&htim14);
			}

			if (Motor[4].NumberofSteps > Motor[4].NumberofSteps_StopAccel)
			{
				if(AccelDecelcount_TIM14 >= Motor[4].AccelerationTimeTMR)
				{
					AccelDecelcount_TIM14=0;
					AccelDecel(ACCEL,&Motor[4]);
				}
			}
			else if (Motor[4].NumberofSteps < Motor[4].NumberofSteps_BeginDecel)
			{
				if(AccelDecelcount_TIM14 >= Motor[4].DecelerationTimeTMR)
				{
					AccelDecelcount_TIM14=0;
					AccelDecel(DECEL,&Motor[4]);
				}
			}
	}

#ifdef ALL_4port_5V
	else if (htim->Instance == TIM6)
	{
			timecount_TIM6++;
			AccelDecelcount_TIM6++;

			if(timecount_TIM6 >= Motor[5].StepperSpeedTMR)
			{
				timecount_TIM6 = 0 ;
				if (Motor[5].MotorDirection == 1){
					switch ( Motor5_State )
					{
					case 1:
						Motor5_AB();
						Motor5_State = 2 ;
						break;
					case 2:
						Motor5_Ab();
						Motor5_State = 3 ;
						break;
					case 3:
						Motor5_ab();
						Motor5_State = 4 ;
						break;
					case 4:
						Motor5_aB();
						Motor5_State = 1 ;
						break;
					}
				}
				else{
					switch ( Motor5_State )
					{
					case 1:
						Motor5_AB();
						Motor5_State = 2 ;
						break;
					case 2:
						Motor5_aB();
						Motor5_State = 3 ;
						break;
					case 3:
						Motor5_ab();
						Motor5_State = 4 ;
						break;
					case 4:
						Motor5_Ab();
						Motor5_State = 1 ;
						break;
					}
				}

				Motor[5].NumberofSteps--;
				if (Motor[5].MotorDirection == 1){
					Motor[5].StepPosition++;
				}
				else{
					Motor[5].StepPosition--;
				}
			}
			if(Motor[5].StepPosition == Motor[5].TargetPosition){
				Motor[5].Status = 0;
				Motor5_Release();
				printf("---Motor5 Steps Position:%ld---\r\n",Motor[5].StepPosition);
				HAL_TIM_Base_Stop_IT(&htim6);
			}
			else if (Motor[5].NumberofSteps <= 0){
				Motor[5].Status = 0;
				Motor5_Release();
				//printf("[WRONG]Motor5 Goto Target Position Failed!---Current_Position:%ld---\r\n",Motor[5].StepPosition);
				HAL_TIM_Base_Stop_IT(&htim6);
			}

			if (Motor[5].NumberofSteps > Motor[5].NumberofSteps_StopAccel){
				if(AccelDecelcount_TIM6 >= Motor[5].AccelerationTimeTMR){
					AccelDecelcount_TIM6=0;
					AccelDecel(ACCEL,&Motor[5]);
				}
			}
			else if (Motor[5].NumberofSteps < Motor[5].NumberofSteps_BeginDecel){
				if(AccelDecelcount_TIM6 >= Motor[5].DecelerationTimeTMR){
					AccelDecelcount_TIM6=0;
					AccelDecel(DECEL,&Motor[5]);
				}
			}
	}

	else if (htim->Instance == TIM7)
	{
			timecount_TIM7++;
			AccelDecelcount_TIM7++;

			if(timecount_TIM7 >= Motor[6].StepperSpeedTMR)
			{
				timecount_TIM7 = 0 ;
				Motor[6].NumberofSteps--;

				if (Motor[6].MotorDirection == 1){
					switch ( Motor6_State )
					{
					case 1:
						Motor6_AB();
						Motor6_State = 2 ;
						break;
					case 2:
						Motor6_Ab();
						Motor6_State = 3 ;
						break;
					case 3:
						Motor6_ab();
						Motor6_State = 4 ;
						break;
					case 4:
						Motor6_aB();
						Motor6_State = 1 ;
						break;
					}
				}
				else{
					switch ( Motor6_State )
					{
					case 1:
						Motor6_AB();
						Motor6_State = 2 ;
						break;
					case 2:
						Motor6_aB();
						Motor6_State = 3 ;
						break;
					case 3:
						Motor6_ab();
						Motor6_State = 4 ;
						break;
					case 4:
						Motor6_Ab();
						Motor6_State = 1 ;
						break;
					}
				}

				if (Motor[6].MotorDirection == 1){
					Motor[6].StepPosition++;
				}
				else{
					Motor[6].StepPosition--;
				}
			}
			if(Motor[6].StepPosition == Motor[6].TargetPosition){
				Motor[6].Status = 0;
				Motor6_Release();
				printf("---Motor[6] Steps Position:%ld---\r\n",Motor[6].StepPosition);
				HAL_TIM_Base_Stop_IT(&htim7);
			}
			else if (Motor[6].NumberofSteps <= 0){
				Motor[6].Status = 0;
				Motor6_Release();
				//printf("[WRONG]Motor[6] Goto Target Position Failed!---Current_Position:%ld---\r\n",Motor[6].StepPosition);
				HAL_TIM_Base_Stop_IT(&htim7);
			}

			if (Motor[6].NumberofSteps > Motor[6].NumberofSteps_StopAccel){
				if(AccelDecelcount_TIM7 >= Motor[6].AccelerationTimeTMR){
					AccelDecelcount_TIM7=0;
					AccelDecel(ACCEL,&Motor[6]);
				}
			}
			else if (Motor[6].NumberofSteps < Motor[6].NumberofSteps_BeginDecel){
				if(AccelDecelcount_TIM7 >= Motor[6].DecelerationTimeTMR){
					AccelDecelcount_TIM7=0;
					AccelDecel(DECEL,&Motor[6]);
				}
			}
	}

	else if (htim->Instance == TIM12)
	{
			timecount_TIM12++;
			AccelDecelcount_TIM12++;

			if(timecount_TIM12 >= Motor[7].StepperSpeedTMR)
			{
				timecount_TIM12 = 0 ;
				Motor[7].NumberofSteps--;

				if (Motor[7].MotorDirection == 1){
					switch ( Motor7_State )
					{
					case 1:
						Motor7_AB();
						Motor7_State = 2 ;
						break;
					case 2:
						Motor7_Ab();
						Motor7_State = 3 ;
						break;
					case 3:
						Motor7_ab();
						Motor7_State = 4 ;
						break;
					case 4:
						Motor7_aB();
						Motor7_State = 1 ;
						break;
					}
				}
				else{
					switch ( Motor7_State )
					{
					case 1:
						Motor7_AB();
						Motor7_State = 2 ;
						break;
					case 2:
						Motor7_aB();
						Motor7_State = 3 ;
						break;
					case 3:
						Motor7_ab();
						Motor7_State = 4 ;
						break;
					case 4:
						Motor7_Ab();
						Motor7_State = 1 ;
						break;
					}
				}

				if (Motor[7].MotorDirection == 1){
					Motor[7].StepPosition++;
				}
				else{
					Motor[7].StepPosition--;
				}
			}
			if(Motor[7].StepPosition == Motor[7].TargetPosition){
				Motor[7].Status = 0;
				Motor7_Release();
				printf("---Motor[7] Steps Position:%ld---\r\n",Motor[7].StepPosition);
				HAL_TIM_Base_Stop_IT(&htim12);
			}
			else if (Motor[7].NumberofSteps <= 0){
				Motor[7].Status = 0;
				Motor7_Release();
				//printf("[WRONG]Motor[7] Goto Target Position Failed!---Current_Position:%ld---\r\n",Motor[7].StepPosition);
				HAL_TIM_Base_Stop_IT(&htim12);
			}

			if (Motor[7].NumberofSteps > Motor[7].NumberofSteps_StopAccel){
				if(AccelDecelcount_TIM12 >= Motor[7].AccelerationTimeTMR){
					AccelDecelcount_TIM12=0;
					AccelDecel(ACCEL,&Motor[7]);
				}
			}
			else if (Motor[7].NumberofSteps < Motor[7].NumberofSteps_BeginDecel){
				if(AccelDecelcount_TIM12 >= Motor[7].DecelerationTimeTMR){
					AccelDecelcount_TIM12=0;
					AccelDecel(DECEL,&Motor[7]);
				}
			}
	}
#endif

#ifdef L298N_StepMotorCtrl
	else if (htim->Instance == TIM6)
	{
			timecount_TIM6++;
			AccelDecelcount_TIM6++;

			if(timecount_TIM6 >= Motor[5].StepperSpeedTMR)
			{
				timecount_TIM6 = 0 ;
				if (Motor[5].MotorDirection == 1){
					switch ( Motor5_State )
					{
					case 1:
						Motor5_AB();
						Motor5_State = 2 ;
						break;
					case 2:
						Motor5_Ab();
						Motor5_State = 3 ;
						break;
					case 3:
						Motor5_ab();
						Motor5_State = 4 ;
						break;
					case 4:
						Motor5_aB();
						Motor5_State = 1 ;
						break;
					}
				}
				else{
					switch ( Motor5_State )
					{
					case 1:
						Motor5_AB();
						Motor5_State = 2 ;
						break;
					case 2:
						Motor5_aB();
						Motor5_State = 3 ;
						break;
					case 3:
						Motor5_ab();
						Motor5_State = 4 ;
						break;
					case 4:
						Motor5_Ab();
						Motor5_State = 1 ;
						break;
					}
				}

				Motor[5].NumberofSteps--;
				if (Motor[5].MotorDirection == 1){
					Motor[5].StepPosition++;
				}
				else{
					Motor[5].StepPosition--;
				}
			}
			if(Motor[5].StepPosition == Motor[5].TargetPosition){
				Motor[5].Status = 0;
				Motor5_Release();
				printf("---Motor5 Steps Position:%ld---\r\n",Motor[5].StepPosition);
				HAL_TIM_Base_Stop_IT(&htim6);
			}
			else if (Motor[5].NumberofSteps <= 0){
				Motor[5].Status = 0;
				Motor5_Release();
				//printf("[WRONG]Motor5 Goto Target Position Failed!---Current_Position:%ld---\r\n",Motor[5].StepPosition);
				HAL_TIM_Base_Stop_IT(&htim6);
			}

			if (Motor[5].NumberofSteps > Motor[5].NumberofSteps_StopAccel){
				if(AccelDecelcount_TIM6 >= Motor[5].AccelerationTimeTMR){
					AccelDecelcount_TIM6=0;
					AccelDecel(ACCEL,&Motor[5]);
				}
			}
			else if (Motor[5].NumberofSteps < Motor[5].NumberofSteps_BeginDecel){
				if(AccelDecelcount_TIM6 >= Motor[5].DecelerationTimeTMR){
					AccelDecelcount_TIM6=0;
					AccelDecel(DECEL,&Motor[5]);
				}
			}
	}

	else if (htim->Instance == TIM7)
	{
			timecount_TIM7++;
			AccelDecelcount_TIM7++;

			if ( get_ADC1_Current_Phase(0) < (abs(Motor6_MicroSteps[Motor6_State][1])*VM6_Full_Current) ){
				if ( Motor6_MicroSteps[Motor6_State][1] > 0 ){
					Motor6_A();
				}else{
					Motor6_a();
				}
			}else{
				Motor6_A_release();
			}

			if ( get_ADC1_Current_Phase(1) < (abs(Motor6_MicroSteps[Motor6_State][2])*VM6_Full_Current) ){
				if ( Motor6_MicroSteps[Motor6_State][2] > 0 ){
					Motor6_B();
				}else{
					Motor6_b();
				}
			}else{
				Motor6_B_release();
			}

			if(timecount_TIM7 >= Motor[6].StepperSpeedTMR)
			{
				timecount_TIM7 = 0 ;
				Motor[6].NumberofSteps--;

				if (Motor[6].MotorDirection == 1){
					Motor6_State += Motor6_MicroSteps_Increment ;
					if ( Motor6_State > 31 ){
						Motor6_State = 0;
					}
				}
				else{
					Motor6_State -= Motor6_MicroSteps_Increment;
					if ( Motor6_State < 0 ){
						Motor6_State = 32 - Motor6_MicroSteps_Increment;
					}
				}

				if (Motor[6].MotorDirection == 1){
					Motor[6].StepPosition++;
				}
				else{
					Motor[6].StepPosition--;
				}

				if(Motor[6].StepPosition == Motor[6].TargetPosition){
					Motor[6].Status = 0;
					Motor6_Release();
					printf("---Motor[6] Steps Position:%ld---\r\n",Motor[6].StepPosition);
					HAL_TIM_Base_Stop_IT(&htim7);
				}
				else if (Motor[6].NumberofSteps <= 0){
					Motor[6].Status = 0;
					Motor6_Release();
					printf("[WRONG]Motor6 Goto Target Position Failed!---Current_Position:%ld---\r\n",Motor[6].StepPosition);
					HAL_TIM_Base_Stop_IT(&htim7);
				}
			}

			if (Motor[6].NumberofSteps > Motor[6].NumberofSteps_StopAccel){
				if(AccelDecelcount_TIM7 >= Motor[6].AccelerationTimeTMR){
					AccelDecelcount_TIM7=0;
					AccelDecel(ACCEL,&Motor[6]);
				}
			}
			else if (Motor[6].NumberofSteps < Motor[6].NumberofSteps_BeginDecel){
				if(AccelDecelcount_TIM7 >= Motor[6].DecelerationTimeTMR){
					AccelDecelcount_TIM7=0;
					AccelDecel(DECEL,&Motor[6]);
				}
			}
	}
#endif

#ifdef CiFenLi
	else if (htim->Instance == TIM12)
	{
			timecount_TIM12_DCM7++;
			timecount_TIM12_DCM6++;
			if (Motor[7].Status){
				if(timecount_TIM12_DCM7 <= Motor[7].AccelerationTimeTMR)
				{
					switch( Motor[7].Status ){
					case 0b00000010:
						VM7_IN1_H();
						break;
					case 0b00000001:
						VM7_IN4_H();
						break;
					case 0b00000011:
						VM7_IN1_H();
						VM7_IN4_H();
						break;
					}
				}
				else if(timecount_TIM12_DCM7 > Motor[7].AccelerationTimeTMR)
				{
					switch( Motor[7].Status ){
					case 0b00000010:
						VM7_IN1_L();
						break;
					case 0b00000001:
						VM7_IN4_L();
						break;
					case 0b00000011:
						VM7_IN1_L();
						VM7_IN4_L();
						break;
					}
				}
				if(timecount_TIM12_DCM7 >= Motor[7].StepperSpeedTMR)
				{
					timecount_TIM12_DCM7 = 0 ;
				}
			}

			if (Motor[6].Status){
				if(timecount_TIM12_DCM6 <= Motor[6].AccelerationTimeTMR)
				{
					switch( Motor[6].Status ){
					case 0b00000010:
						VM6_IN1_H();
						break;
					case 0b00000001:
						VM6_IN4_H();
						break;
					case 0b00000011:
						VM6_IN1_H();
						VM6_IN4_H();
						break;
					}
				}
				else if(timecount_TIM12_DCM6 > Motor[6].AccelerationTimeTMR)
				{
					switch( Motor[6].Status ){
					case 0b00000010:
						VM6_IN1_L();
						break;
					case 0b00000001:
						VM6_IN4_L();
						break;
					case 0b00000011:
						VM6_IN1_L();
						VM6_IN4_L();
						break;
					}
				}
				if(timecount_TIM12_DCM6 >= Motor[6].StepperSpeedTMR)
				{
					timecount_TIM12_DCM6 = 0 ;
				}
			}
	}
#endif

#ifdef JiaYangZhen
	else if (htim->Instance == TIM12)
	{
			timecount_TIM12_DCM7++;
			timecount_TIM12_DCM8++;
			if (Motor[7].Status){
				if(timecount_TIM12_DCM7 <= Motor[7].AccelerationTimeTMR)
				{
					switch( Motor[7].Status ){
					case 0b00000010:
						VM7_IN1_H();
						break;
					case 0b00000001:
						VM7_IN4_H();
						break;
					case 0b00000011:
						VM7_IN1_H();
						VM7_IN4_H();
						break;
					}
				}
				else if(timecount_TIM12_DCM7 > Motor[7].AccelerationTimeTMR)
				{
					switch( Motor[7].Status ){
					case 0b00000010:
						VM7_IN1_L();
						break;
					case 0b00000001:
						VM7_IN4_L();
						break;
					case 0b00000011:
						VM7_IN1_L();
						VM7_IN4_L();
						break;
					}
				}
				if(timecount_TIM12_DCM7 >= Motor[7].StepperSpeedTMR)
				{
					timecount_TIM12_DCM7 = 0 ;
				}
			}

			if (Motor[8].Status){
				if(timecount_TIM12_DCM8 <= Motor[8].AccelerationTimeTMR)
				{
					switch( Motor[8].Status ){
					case 0b00000010:
						VM8_IN1_H();
						break;
					case 0b00000001:
						VM8_IN4_H();
						break;
					case 0b00000011:
						VM8_IN1_H();
						VM8_IN4_H();
						break;
					}
				}
				else if(timecount_TIM12_DCM8 > Motor[8].AccelerationTimeTMR)
				{
					switch( Motor[8].Status ){
					case 0b00000010:
						VM8_IN1_L();
						break;
					case 0b00000001:
						VM8_IN4_L();
						break;
					case 0b00000011:
						VM8_IN1_L();
						VM8_IN4_L();
						break;
					}
				}
				if(timecount_TIM12_DCM8 >= Motor[8].StepperSpeedTMR)
				{
					timecount_TIM12_DCM8 = 0 ;
				}
			}
	}
#endif

#ifdef QuanxiePVctrl
	else if (htim->Instance == TIM12)
	{
			timecount_TIM12_DCM7++;
			timecount_TIM12_DCM8++;
			if (Motor[7].Status){
				if(timecount_TIM12_DCM7 <= Motor[7].AccelerationTimeTMR)
				{
					switch( Motor[7].Status ){
					case 0b00000010:
						VM7_IN1_H();
						break;
					case 0b00000001:
						VM7_IN4_H();
						break;
					case 0b00000011:
						VM7_IN1_H();
						VM7_IN4_H();
						break;
					}
				}
				else if(timecount_TIM12_DCM7 > Motor[7].AccelerationTimeTMR)
				{
					switch( Motor[7].Status ){
					case 0b00000010:
						VM7_IN1_L();
						break;
					case 0b00000001:
						VM7_IN4_L();
						break;
					case 0b00000011:
						VM7_IN1_L();
						VM7_IN4_L();
						break;
					}
				}
				if(timecount_TIM12_DCM7 >= Motor[7].StepperSpeedTMR)
				{
					timecount_TIM12_DCM7 = 0 ;
				}
			}

			if (Motor[8].Status){
				if(timecount_TIM12_DCM8 <= Motor[8].AccelerationTimeTMR)
				{
					switch( Motor[8].Status ){
					case 0b00000010:
						VM8_IN1_H();
						break;
					case 0b00000001:
						VM8_IN4_H();
						break;
					case 0b00000011:
						VM8_IN1_H();
						VM8_IN4_H();
						break;
					}
				}
				else if(timecount_TIM12_DCM8 > Motor[8].AccelerationTimeTMR)
				{
					switch( Motor[8].Status ){
					case 0b00000010:
						VM8_IN1_L();
						break;
					case 0b00000001:
						VM8_IN4_L();
						break;
					case 0b00000011:
						VM8_IN1_L();
						VM8_IN4_L();
						break;
					}
				}
				if(timecount_TIM12_DCM8 >= Motor[8].StepperSpeedTMR)
				{
					timecount_TIM12_DCM8 = 0 ;
				}
			}
	}
#endif
  /* USER CODE END Callback 1 */
}

void Error_Handler(void)
{
  __disable_irq();
  while (1)
  {
  }
}

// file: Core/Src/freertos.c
/* USER CODE BEGIN Header */
/**
  ******************************************************************************
  * File Name          : freertos.c
  * Description        : Code for freertos applications
  ******************************************************************************
  * @attention
  *
  * Copyright (c) 2022 STMicroelectronics.
  * All rights reserved.
  *
  * This software is licensed under terms that can be found in the LICENSE file
  * in the root directory of this software component.
  * If no LICENSE file comes with this software, it is provided AS-IS.
  *
  ******************************************************************************
  */
/* USER CODE END Header */

#include "FreeRTOS.h"
#include "task.h"
#include "main.h"
#include "cmsis_os.h"

/* Definitions for defaultTask */
osThreadId_t defaultTaskHandle;
const osThreadAttr_t defaultTask_attributes = {
  .name = "defaultTask",
  .stack_size = 128 * 4,
  .priority = (osPriority_t) osPriorityLow,
};
/* Definitions for messageTask */
osThreadId_t messageTaskHandle;
const osThreadAttr_t messageTask_attributes = {
  .name = "messageTask",
  .stack_size = 512 * 4,
  .priority = (osPriority_t) osPriorityNormal,
};
/* Definitions for myTask03 */
osThreadId_t myTask03Handle;
const osThreadAttr_t myTask03_attributes = {
  .name = "myTask03",
  .stack_size = 512 * 4,
  .priority = (osPriority_t) osPriorityNormal,
};
/* Definitions for DetectionTask */
osThreadId_t DetectionTaskHandle;
const osThreadAttr_t DetectionTask_attributes = {
  .name = "DetectionTask",
  .stack_size = 512 * 4,
  .priority = (osPriority_t) osPriorityLow,
};

void StartDefaultTask(void *argument);
void StartmessageTask(void *argument);
void StartTask03(void *argument);
void StartDetectionTask(void *argument);

void MX_FREERTOS_Init(void); /* (MISRA C 2004 rule 8.1) */

void MX_FREERTOS_Init(void) {

  /* Create the thread(s) */
  /* creation of defaultTask */
  defaultTaskHandle = osThreadNew(StartDefaultTask, NULL, &defaultTask_attributes);

  /* creation of messageTask */
  messageTaskHandle = osThreadNew(StartmessageTask, NULL, &messageTask_attributes);

  /* creation of myTask03 */
  myTask03Handle = osThreadNew(StartTask03, NULL, &myTask03_attributes);

  /* creation of DetectionTask */
  //DetectionTaskHandle = osThreadNew(StartDetectionTask, NULL, &DetectionTask_attributes);

}

void StartDefaultTask(void *argument)
{
  /* USER CODE BEGIN StartDefaultTask */
  /* Infinite loop */
  for(;;)
  {
	  LED_Heart_Toggle();
	  osDelay(1000);
  }
  /* USER CODE END StartDefaultTask */
}

__weak void StartmessageTask(void *argument)
{
  for(;;)
  {
    osDelay(1);
  }
}

__weak void StartTask03(void *argument)
{
  for(;;)
  {
    osDelay(1);
  }
}

__weak void StartDetectionTask(void *argument)
{
  /* USER CODE BEGIN StartDetectionTask */
  /* Infinite loop */
  for(;;)
  {
    osDelay(10000);
  }
  /* USER CODE END StartDetectionTask */
}
